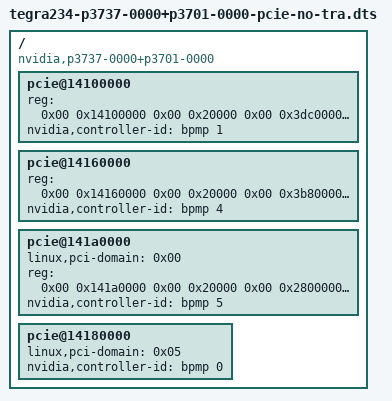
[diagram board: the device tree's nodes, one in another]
// SPDX-License-Identifier: GPL-2.0-only
// SPDX-FileCopyrightText: Copyright (c) 2023 NVIDIA CORPORATION & AFFILIATES. All rights reserved.

/dts-v1/;
/plugin/;

/ {
	compatible = "nvidia,p3737-0000+p3701-0000", "nvidia,p3701-0000", "nvidia,tegra234";

    fragment-pcie-no-tra-overrides@0 {
        target-path = "/";
        __overlay__ {
            pcie@14100000 {
                reg = <0x00 0x14100000 0x00 0x20000
                       0x00 0x3dc00000 0x00 0x40000
                       0x00 0x3dc40000 0x00 0x40000
                       0x00 0x3dc80000 0x00 0x40000
                       0x20 0xb0000000 0x00 0x10000000>;
                ranges = <0x81000000 0x00 0x3dd00000 0x00 0x3dd00000 0x00 0x100000
                          0x82000000 0x00 0x3de00000 0x00 0x3de00000 0x00 0x2200000
                          0xc3000000 0x20 0x80000000 0x20 0x80000000 0x00 0x28000000>;
                nvidia,controller-id = <&bpmp 1>;
            };

            pcie@14160000 {
                reg = <0x00 0x14160000 0x00 0x20000
                       0x00 0x3b800000 0x00 0x40000
                       0x00 0x3b840000 0x00 0x40000
                       0x00 0x3b880000 0x00 0x40000
                       0x24 0x30000000 0x00 0x10000000>;
                ranges = <0x81000000 0x00 0x3b900000 0x00 0x3b900000 0x00 0x100000
                          0x82000000 0x00 0x3ba00000 0x00 0x3ba00000 0x00 0x2200000
                          0xc3000000 0x21 0x40000000 0x21 0x40000000 0x02 0xe8000000>;
                nvidia,controller-id = <&bpmp 4>;
            };

            pcie@141a0000 {
                linux,pci-domain = <0x00>;
                reg = <0x00 0x141a0000 0x00 0x20000
                       0x00 0x28000000 0x00 0x40000
                       0x00 0x28040000 0x00 0x40000
                       0x00 0x28080000 0x00 0x40000
                       0x2b 0x30000000 0x00 0x10000000>;
                ranges = <0x81000000 0x00 0x28100000 0x00 0x28100000 0x00 0x100000
                          0x82000000 0x00 0x28200000 0x00 0x28200000 0x00 0x13600000
			  0x43000000 0x28 0x00000000 0x28 0x00000000 0x03 0x28000000>;
                nvidia,controller-id = <&bpmp 5>;
            };

            pcie@14180000 {
                linux,pci-domain = <0x05>;
                nvidia,controller-id = <&bpmp 0>;
            };
        };
    };
};
